# N32H480 register map
Vendor: Nationstech Ltd.; File version: 1.0
Registers are 32-bit, read-write, reset 0x0 unless marked. A register's access mark holds for its fields unless they carry their own. Offsets are from the block's base; [hi:lo] are bit positions; {n}, {i} and the like mark numbered series.

## SDIO
Base 0x40021400
0x00 SDIO_PWRCTRL — SDIO power control register
  [1:0] PWRCTRL — Power supply control bits
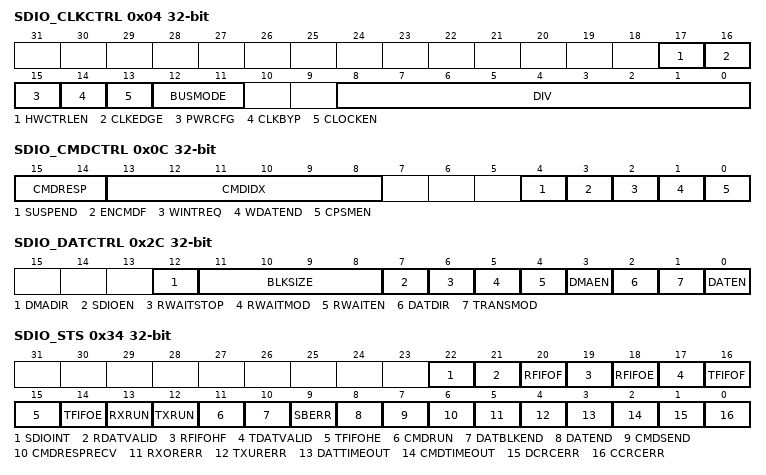
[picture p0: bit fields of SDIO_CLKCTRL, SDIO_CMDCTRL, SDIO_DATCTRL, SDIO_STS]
0x04 SDIO_CLKCTRL — SDIO clock control register
  [17] HWCTRLEN — HW Flow Control enable
  [16] CLKEDGE — SDIO_CLK dephasing selection bit
  [15] PWRCFG — Power saving configuration bit
  [14] CLKBYP — Clock divider bypass enable bit
  [13] CLOCKEN — Clock enable bit
  [12:11] BUSMODE — Wide bus mode enable bit
  [8:0] DIV — Clock divide factor
0x08 SDIO_CMDARG — SDIO command argument register
  [31:0] CMDARG — Command argument
0x0C SDIO_CMDCTRL — SDIO command register
  [15:14] CMDRESP — Wait for response bits
  [13:8] CMDIDX — Command index
  [4] SUSPEND — SD I/O suspend command
  [3] ENCMDF — Enable CMD completion
  [2] WINTREQ — CPSM waits for interrupt request
  [1] WDATEND — CPSM Waits for ends of data transfer
  [0] CPSMEN — Command path state machine (CPSM) Enable bit
0x10 SDIO_CMDRESP ro — SDIO command response register
  [5:0] RESPCMDIDX — Response command index
{0x10+4i} SDIO_RESPONSE{i} ro (i=1..4) — SDIO response register {i}
  [31:0] CARDSTS{i} — Card Status {i}
0x24 SDIO_DTIMER — SDIO data timer register
  [31:0] DATTIMEOUT — Data timeout period
0x28 SDIO_DATLEN — SDIO data length register
  [24:0] DATLEN — Data length value
0x2C SDIO_DATCTRL — SDIO data control register
  [12] DMADIR — DMA direction
  [11:8] BLKSIZE — Data block size
  [7] SDIOEN — SD I/O enable functions
  [6] RWAITSTOP — Read wait stop
  [5] RWAITMOD — Read wait mode
  [4] RWAITEN — Read wait start
  [3] DMAEN — DMA enable
  [2] DATDIR — Data transfer direction selection
  [1] TRANSMOD — Data transfer mode selection
  [0] DATEN — Data transfer enabled bit
0x30 SDIO_DATCOUNT — SDIO data counter register
  [24:0] DATCOUNT — Data count value
0x34 SDIO_STS — SDIO status register
  [22] SDIOINT — SDIO interrupt received
  [21] RDATVALID — Data available in receive FIFO
  [20] RFIFOF — Receive FIFO full
  [19] RFIFOHF — Receive FIFO half full
  [18] RFIFOE — Receive FIFO empty
  [17] TDATVALID — Data available in transmit FIFO
  [16] TFIFOF — Transmit FIFO full
  [15] TFIFOHE — Transmit FIFO half full
  [14] TFIFOE — Transmit FIFO empty
  [13] RXRUN — Data receive in progress
  [12] TXRUN — Data transmit in progress
  [11] CMDRUN — Command transfer in progress
  [10] DATBLKEND — Data block sent/received
  [9] SBERR — Start bit not detected on all data signals in wide bus mode
  [8] DATEND — Data end
  [7] CMDSEND — Command sent
  [6] CMDRESPRECV — Command response
  [5] RXORERR — Received FIFO overrun error
  [4] TXURERR — Transmit FIFO underrun error
  [3] DATTIMEOUT — Data timeout
  [2] CMDTIMEOUT — Command response timeout
  [1] DCRCERR — Data block sent/received
  [0] CCRCERR — Command response received
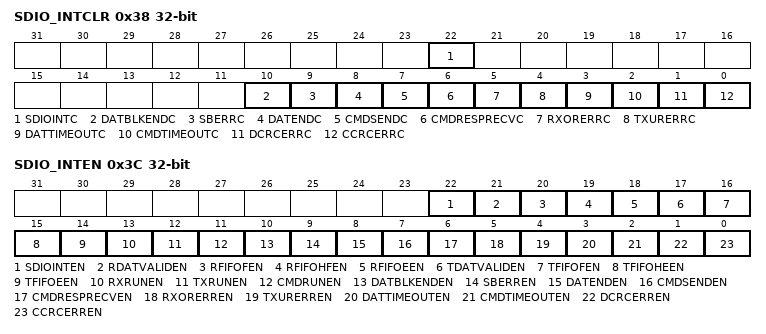
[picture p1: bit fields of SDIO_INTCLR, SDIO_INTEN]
0x38 SDIO_INTCLR — SDIO interrupt clear register
  [22] SDIOINTC — SDIOINT flag clear bit
  [10] DATBLKENDC — DATBLKEND flag clear bit
  [9] SBERRC — SBERR flag clear bit
  [8] DATENDC — DATEND flag clear bit
  [7] CMDSENDC — CMDSEND flag clear bit
  [6] CMDRESPRECVC — CMDRESPRECV flag clear bit
  [5] RXORERRC — RXORERR flag clear bit
  [4] TXURERRC — TXURERR flag clear bit
  [3] DATTIMEOUTC — DATTIMEOUT flag clear bit
  [2] CMDTIMEOUTC — CMDTIMEOUT flag clear bit
  [1] DCRCERRC — DCRCERR flag clear bit
  [0] CCRCERRC — CCRCERR clear bit
0x3C SDIO_INTEN — SDIO interrupt enable register
  [22] SDIOINTEN — SDIO mode interrupt received interrupt enable
  [21] RDATVALIDEN — Data available in Rx FIFO interrupt enable
  [20] RFIFOFEN — Rx FIFO full interrupt enable
  [19] RFIFOHFEN — Rx FIFO half full interrupt enable
  [18] RFIFOEEN — Rx FIFO empty interrupt enable
  [17] TDATVALIDEN — Data available in Rx FIFO interrupt enable
  [16] TFIFOFEN — Tx FIFO full interrupt enable
  [15] TFIFOHEEN — Tx FIFO half full interrupt enable
  [14] TFIFOEEN — Tx FIFO empty interrupt enable
  [13] RXRUNEN — Data receive acting interrupt enable
  [12] TXRUNEN — Data transmit acting interrupt enable
  [11] CMDRUNEN — Command transmit acting interrupt enable
  [10] DATBLKENDEN — Data block end interrupt enable
  [9] SBERREN — Start bit error interrupt enable
  [8] DATENDEN — Data end interrupt enable
  [7] CMDSENDEN — Command sent interrupt enable
  [6] CMDRESPRECVEN — Command response received interrupt enable
  [5] RXORERREN — Rx FIFO overrun error interrupt enable
  [4] TXURERREN — Tx FIFO underrun error interrupt enable
  [3] DATTIMEOUTEN — Data timeout interrupt enable
  [2] CMDTIMEOUTEN — Command timeout interrupt enable
  [1] DCRCERREN — Data CRC fail interrupt enable
  [0] CCRCERREN — Command CRC fail interrupt enable
0x48 SDIO_FIFOCOUNT — SDIO FIFO counter register
  [23:0] FIFOCOUNT — The number of data words to be written to or read from the FIFO
0x80 SDIO_DATFIFO — SDIO data FIFO register
  [31:0] FIFIDAT — Receive and transmit FIFO data
